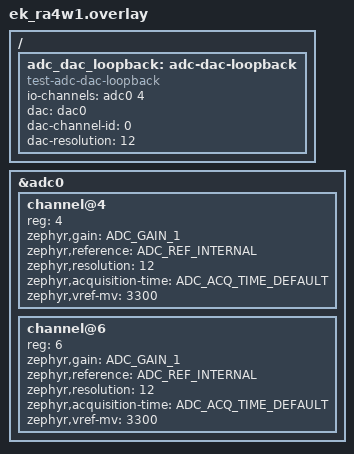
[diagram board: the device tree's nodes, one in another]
/*
 * Copyright (c) 2024 Renesas Electronics Corporation
 *
 * SPDX-License-Identifier: Apache-2.0
 */

&adc0 {
	status = "okay";
	#address-cells = <1>;
	#size-cells = <0>;

	channel@4 {
		reg = <4>;
		zephyr,gain = "ADC_GAIN_1";
		zephyr,reference = "ADC_REF_INTERNAL";
		zephyr,resolution = <12>;
		zephyr,acquisition-time = <ADC_ACQ_TIME_DEFAULT>;
		zephyr,vref-mv = <3300>;
	};

	channel@6 {
		reg = <6>;
		zephyr,gain = "ADC_GAIN_1";
		zephyr,reference = "ADC_REF_INTERNAL";
		zephyr,resolution = <12>;
		zephyr,acquisition-time = <ADC_ACQ_TIME_DEFAULT>;
		zephyr,vref-mv = <3300>;
	};
};

/ {
	adc_dac_loopback: adc-dac-loopback {
		compatible = "test-adc-dac-loopback";
		io-channels = <&adc0 4>;
		dac = <&dac0>;
		dac-channel-id = <0>;
		dac-resolution = <12>;
	};
};
